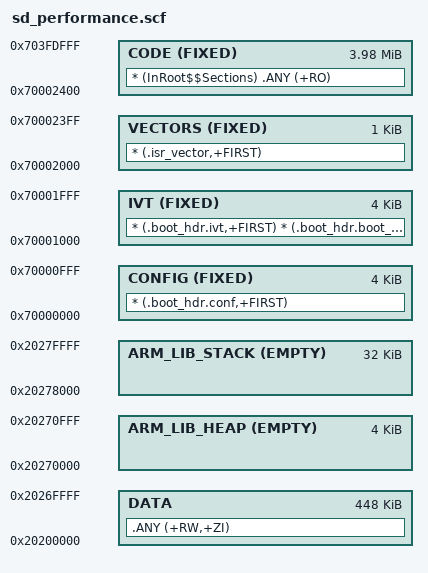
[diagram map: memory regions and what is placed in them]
LR_FLASH 0x70000000 0x003FE000 {
 CONFIG 0x70000000 FIXED 0x1000 { * (.boot_hdr.conf,+FIRST) }
 IVT 0x70001000 FIXED 0x1000 { * (.boot_hdr.ivt,+FIRST) * (.boot_hdr.boot_data) }
 VECTORS 0x70002000 FIXED 0x400 { * (.isr_vector,+FIRST) }
 CODE 0x70002400 FIXED 0x003FBC00 { * (InRoot$$Sections) .ANY (+RO) }
 DATA 0x20200000 0x00070000 { .ANY (+RW,+ZI) }
 ARM_LIB_HEAP 0x20270000 EMPTY 0x1000 {}
 ARM_LIB_STACK 0x20280000 EMPTY -0x8000 {}
}
